# iostr910fa register map
Registers from a debugger description file.
Registers are 32-bit, access not given, no defined reset value unless marked. A register's access mark holds for its fields unless they carry their own. Addresses are absolute; registers are grouped by the start of their names; lines under a group give offsets from that group; [hi:lo] are bit positions; {n}, {i} and the like mark numbered series; 'fields as' and 'values as' point back to an identical list; <NAME> marks a mode.

## FMI
0x44000000 FMI_BBSR_BUF
  [3:0] BBSIZE
0x44000004 FMI_NBBSR_BUF
  [3:0] NBBSIZE
0x4400000C FMI_BBADR_BUF
  [23:0] BBADDR
0x44000010 FMI_NBBADR_BUF
  [23:0] NBBADDR
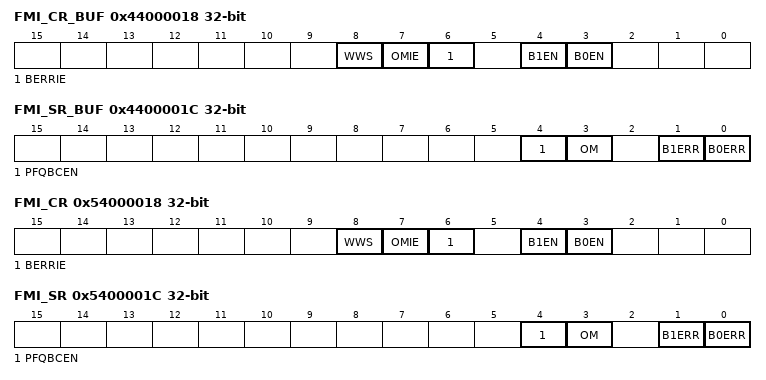
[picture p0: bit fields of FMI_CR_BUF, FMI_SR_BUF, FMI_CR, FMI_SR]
0x44000018 FMI_CR_BUF
  [8] WWS, [7] OMIE, [6] BERRIE, [4] B1EN, [3] B0EN
0x4400001C FMI_SR_BUF
  [4] PFQBCEN, [3] OM, [1] B1ERR, [0] B0ERR
0x44000020 FMI_BCE16ADDR_BUF
  [23:0] BCE16ADDR
0x54000000 FMI_BBSR
  [3:0] BBSIZE
0x54000004 FMI_NBBSR
  [3:0] NBBSIZE
0x5400000C FMI_BBADR
  [23:0] BBADDR
0x54000010 FMI_NBBADR
  [23:0] NBBADDR
0x54000018 FMI_CR
  [8] WWS, [7] OMIE, [6] BERRIE, [4] B1EN, [3] B0EN
0x5400001C FMI_SR
  [4] PFQBCEN, [3] OM, [1] B1ERR, [0] B0ERR
0x54000020 FMI_BCE16ADDR
  [23:0] BCE16ADDR

## EMI
{0x63FFFFE0+0x20*i} EMI_ICR{i}_BUF (i=1..3)
  [3:0] IDCY
{0x63FFFFE4+0x20*i} EMI_RCR{i}_BUF (i=1..3)
  [4:0] WSTRD
{0x63FFFFE8+0x20*i} EMI_WCR{i}_BUF (i=1..3)
  [4:0] WSTWR
{0x63FFFFEC+0x20*i} EMI_OECR{i}_BUF (i=1..3)
  [3:0] WSTOEN
{0x63FFFFF0+0x20*i} EMI_WECR{i}_BUF (i=1..3)
  [3:0] WSTWEN
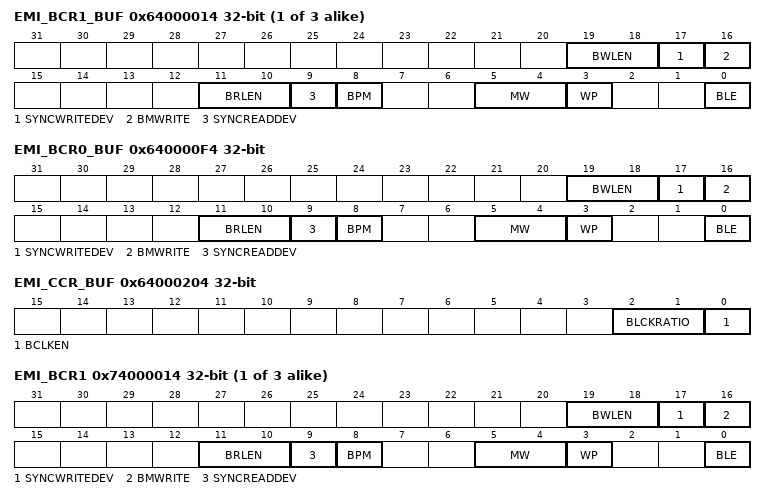
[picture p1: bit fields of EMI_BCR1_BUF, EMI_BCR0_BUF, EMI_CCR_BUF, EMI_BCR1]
{0x63FFFFF4+0x20*i} EMI_BCR{i}_BUF (i=1..3)
  [19:18] BWLEN, [17] SYNCWRITEDEV, [16] BMWRITE, [11:10] BRLEN, [9] SYNCREADDEV, [8] BPM, [5:4] MW, [3] WP, [0] BLE
{0x63FFFFFC+0x20*i} EMI_BRDCR{i}_BUF (i=1..3)
  [4:0] WSTBRD
0x640000E0 EMI_ICR0_BUF
  [3:0] IDCY
0x640000E4 EMI_RCR0_BUF
  [4:0] WSTRD
0x640000E8 EMI_WCR0_BUF
  [4:0] WSTWR
0x640000EC EMI_OECR0_BUF
  [3:0] WSTOEN
0x640000F0 EMI_WECR0_BUF
  [3:0] WSTWEN
0x640000F4 EMI_BCR0_BUF
  fields as EMI_BCR1_BUF
0x640000FC EMI_BRDCR0_BUF
  [4:0] WSTBRD
0x64000204 EMI_CCR_BUF
  [2:1] BLCKRATIO, [0] BCLKEN
{0x73FFFFE0+0x20*i} EMI_ICR{i} (i=1..3)
  [3:0] IDCY
{0x73FFFFE4+0x20*i} EMI_RCR{i} (i=1..3)
  [4:0] WSTRD
{0x73FFFFE8+0x20*i} EMI_WCR{i} (i=1..3)
  [4:0] WSTWR
{0x73FFFFEC+0x20*i} EMI_OECR{i} (i=1..3)
  [3:0] WSTOEN
{0x73FFFFF0+0x20*i} EMI_WECR{i} (i=1..3)
  [3:0] WSTWEN
{0x73FFFFF4+0x20*i} EMI_BCR{i} (i=1..3)
  fields as EMI_BCR1_BUF
{0x73FFFFFC+0x20*i} EMI_BRDCR{i} (i=1..3)
  [4:0] WSTBRD
0x740000E0 EMI_ICR0
  [3:0] IDCY
0x740000E4 EMI_RCR0
  [4:0] WSTRD
0x740000E8 EMI_WCR0
  [4:0] WSTWR
0x740000EC EMI_OECR0
  [3:0] WSTOEN
0x740000F0 EMI_WECR0
  [3:0] WSTWEN
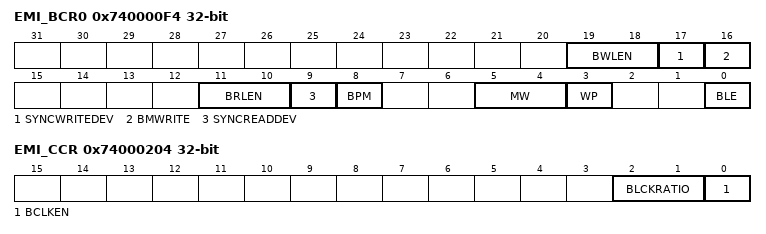
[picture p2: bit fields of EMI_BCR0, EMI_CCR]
0x740000F4 EMI_BCR0
  fields as EMI_BCR1_BUF
0x740000FC EMI_BRDCR0
  [4:0] WSTBRD
0x74000204 EMI_CCR
  [2:1] BLCKRATIO, [0] BCLKEN

## GPIO0
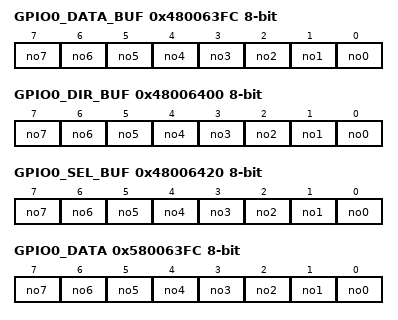
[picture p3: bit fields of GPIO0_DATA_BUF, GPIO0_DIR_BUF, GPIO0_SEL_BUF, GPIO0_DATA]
0x480063FC GPIO0_DATA_BUF 8-bit
  [n] no{n} (n=0..7)
0x48006400 GPIO0_DIR_BUF 8-bit
  [n] no{n} (n=0..7)
0x48006420 GPIO0_SEL_BUF 8-bit
  [n] no{n} (n=0..7)
0x580063FC GPIO0_DATA 8-bit
  [n] no{n} (n=0..7)
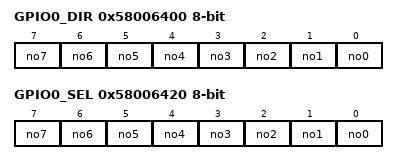
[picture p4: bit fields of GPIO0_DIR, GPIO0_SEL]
0x58006400 GPIO0_DIR 8-bit
  [n] no{n} (n=0..7)
0x58006420 GPIO0_SEL 8-bit
  [n] no{n} (n=0..7)

## GPIO1
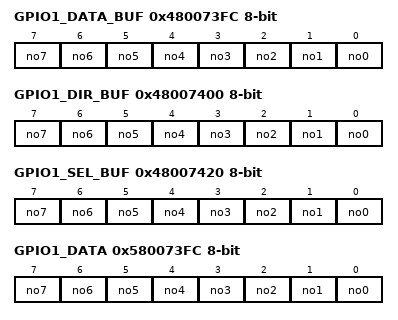
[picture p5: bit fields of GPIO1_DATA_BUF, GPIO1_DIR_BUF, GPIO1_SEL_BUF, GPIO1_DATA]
0x480073FC GPIO1_DATA_BUF 8-bit
  [n] no{n} (n=0..7)
0x48007400 GPIO1_DIR_BUF 8-bit
  [n] no{n} (n=0..7)
0x48007420 GPIO1_SEL_BUF 8-bit
  [n] no{n} (n=0..7)
0x580073FC GPIO1_DATA 8-bit
  [n] no{n} (n=0..7)
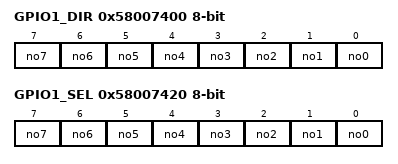
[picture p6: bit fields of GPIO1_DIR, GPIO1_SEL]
0x58007400 GPIO1_DIR 8-bit
  [n] no{n} (n=0..7)
0x58007420 GPIO1_SEL 8-bit
  [n] no{n} (n=0..7)

## GPIO2
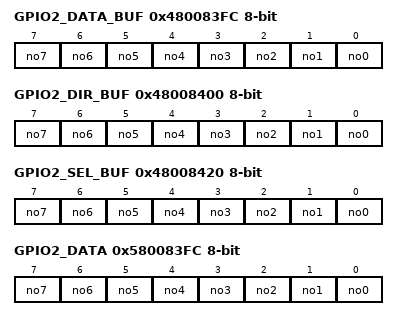
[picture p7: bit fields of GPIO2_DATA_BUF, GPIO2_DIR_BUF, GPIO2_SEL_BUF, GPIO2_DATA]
0x480083FC GPIO2_DATA_BUF 8-bit
  [n] no{n} (n=0..7)
0x48008400 GPIO2_DIR_BUF 8-bit
  [n] no{n} (n=0..7)
0x48008420 GPIO2_SEL_BUF 8-bit
  [n] no{n} (n=0..7)
0x580083FC GPIO2_DATA 8-bit
  [n] no{n} (n=0..7)
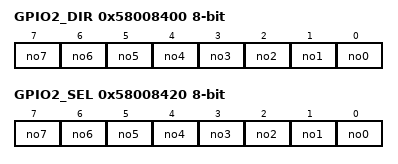
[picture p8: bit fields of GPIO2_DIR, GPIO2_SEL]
0x58008400 GPIO2_DIR 8-bit
  [n] no{n} (n=0..7)
0x58008420 GPIO2_SEL 8-bit
  [n] no{n} (n=0..7)
